# earlgrey register map
Vendor: lowRISC; File version: 0.1
CPU: ibex rev01, little endian, no MPU, no FPU, VTOR, 2 interrupt priority bits, 2 interrupts
Registers are 32-bit, read-write, no defined reset value unless marked. A register's access mark holds for its fields unless they carry their own. Offsets are from the block's base; [hi:lo] are bit positions; {n}, {i} and the like mark numbered series.

## PWM_AON — Transmission of pulse-width modulated output signals with adjustable duty cycle
Base 0x40450000
0x40 REGWEN — Register write enable for all control registers
  [0] Value — When true, all writable registers can be modified. When false, they become read-only. Defaults true, write zero to clear. This can be cleared after initial configuration at boot in order to lock in the listed register settings.
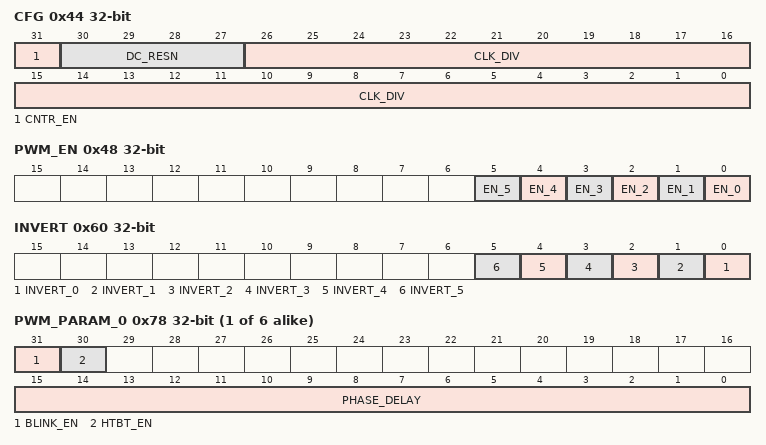
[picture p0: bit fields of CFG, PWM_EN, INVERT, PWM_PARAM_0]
0x44 CFG — Configuration register
  [31] CNTR_EN — Assert this bit to enable the PWM phase counter. Clearing this bit disables and resets the phase counter.
  [30:27] DC_RESN — Phase Resolution (logarithmic). All duty-cycle and phase shift registers represent fractional PWM cycles, expressed in units of 2^16 PWM cycles. Each PWM cycle is divided into 2^(DC_RESN+1) time slices, and thus only the (DC_RESN+1) most significant bits of each phase or duty cycle register are relevant.
  [26:0] CLK_DIV — Sets the period of each PWM beat to be (CLK_DIV+1) input clock periods. Since PWM pulses are generated once every 2^(DC_RESN+1) beats, the period between output pulses is 2^(DC_RESN+1)*(CLK_DIV+1) times longer than the input clock period.
0x48 PWM_EN — Enable PWM operation for each channel
  [n] EN_{n} (n=0..5) — Write 1 to this bit to enable PWM pulses on the corresponding channel.
0x60 INVERT — Invert the PWM output for each channel
  [n] INVERT_{n} (n=0..5) — Write 1 to this bit to invert the output for each channel, so that the corresponding output is active-low.
{0x78+4i} PWM_PARAM_{i} (i=0..5) — Basic PWM Channel Parameters
  [31] BLINK_EN — Enables blink (or heartbeat). If cleared, the output duty cycle will remain constant at DUTY_CYCLE.A. Enabling this bit causes the PWM duty cycle to fluctuate between DUTY_CYCLE.A and DUTY_CYCLE.B
  [30] HTBT_EN — Modulates blink behavior to create a heartbeat effect. When HTBT_EN is set, the duty cycle increases (or decreases) linearly from DUTY_CYCLE.A to DUTY_CYCLE.B and back, in steps of (BLINK_PARAM.Y+1), with an increment (decrement) once every (BLINK_PARAM.X+1) PWM cycles. When HTBT_EN is cleared, the standard blink behavior applies, meaning that the output duty cycle alternates between DUTY_CYCLE.A for (BLINK_PARAM.X+1) pulses and DUTY_CYCLE.B for (BLINK_PARAM.Y+1) pulses.
  [15:0] PHASE_DELAY — Phase delay of the PWM rising edge, in units of 2^(-16) PWM cycles
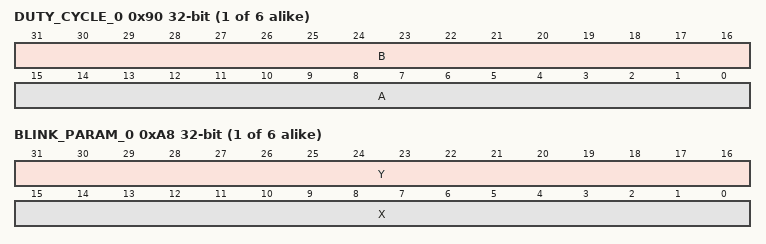
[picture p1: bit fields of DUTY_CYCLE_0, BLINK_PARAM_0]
{0x90+4i} DUTY_CYCLE_{i} (i=0..5) — Controls the duty_cycle of each channel.
  [31:16] B — The target duty cycle for PWM output, in units of 2^(-16)ths of a pulse cycle. The actual precision is however limited to the (DC_RESN+1) most significant bits. This setting only applies when blinking, and determines the target duty cycle.
  [15:0] A — The initial duty cycle for PWM output, in units of 2^(-16)ths of a pulse cycle. The actual precision is however limited to the (DC_RESN+1) most significant bits. This setting applies continuously when not blinking and determines the initial duty cycle when blinking.
{0xA8+4i} BLINK_PARAM_{i} (i=0..5) — Hardware controlled blink/heartbeat parameters.
  [31:16] Y — This blink-rate timing parameter has two different interpretations depending on whether or not the heartbeat feature is enabled. If heartbeat is disabled, a blinking PWM will pulse at duty cycle B for (Y+1) pulse cycles before returning to duty cycle A. If heartbeat is enabled the duty cycle will increase (or decrease) by (Y+1) units every time it is incremented (or decremented)
  [15:0] X — This blink-rate timing parameter has two different interpretations depending on whether or not the heartbeat feature is enabled. If heartbeat is disabled, a blinking PWM will pulse at duty cycle A for (X+1) pulses before switching to duty cycle B. If heartbeat is enabled the duty-cycle will start at the duty cycle A, but will be incremented (or decremented) every (X+1) cycles. In heartbeat mode is enabled, the size of each step is controlled by BLINK_PARAM.Y.
